AUTOSAR XML (schema 4-3-0)
package /Impl_SWC_INP_ARPkg
  swc implementation Impl_SWC_INP_type: programming-language=C, sw-version=1.0.0, vendor-id=0, behavior=SWC_INP_type_IB
    code-descriptors:
      code SRC: artifact-descriptors=autosar-engineering-object={short-label=EngObject, category=SWSRC}
    resource consumption ResourceConsumption
      memory section Mem_SWC_INP_CAL: size=0, sw-addrmethod=CAL, symbol=CAL
      memory section Mem_SWC_INP_CODE: size=0, sw-addrmethod=CODE, symbol=CODE
package /Impl_Type_INP_ARPkg
  16 x impl type:
    BINP_CAN1_outputs: category=STRUCTURE
      63 x element, all with category=TYPE_REFERENCE:
        VINP_CANMsgValidACBTMSC10000_flg: implementation-data-type=boolean
        VINP_CANMsgValidACBTMSC10001_flg: implementation-data-type=boolean
        VINP_CANMsgValidACBTMSC10004_flg: implementation-data-type=boolean
        VINP_CANMsgValidACBTMSC50000_flg: implementation-data-type=boolean
        VINP_CANMsgValidASC1A_flg: implementation-data-type=boolean
        VINP_CANMsgValidEBC1_flg: implementation-data-type=boolean
        VINP_CANMsgValidEBC2_flg: implementation-data-type=boolean
        VINP_CANMsgValidEBC5_flg: implementation-data-type=boolean
        VINP_CANMsgValidECASDM1_flg: implementation-data-type=boolean
        VINP_CANMsgValidEMC1EM1_flg: implementation-data-type=boolean
        VINP_CANMsgValidHRW_flg: implementation-data-type=boolean
        VINP_CANMsgValidTC1_flg: implementation-data-type=boolean
        VINP_ACAmbTemp_C: implementation-data-type=float32
        VINP_ACFanSpdSta_enum: implementation-data-type=uint8
        VINP_TM2BFaultCode_enum: implementation-data-type=uint8
        VINP_ACTempSetSta_C: implementation-data-type=float32
        VINP_ASC1KneelingInfo_enum: implementation-data-type=uint8
        VINP_ABSFullyOper_enum: implementation-data-type=uint8
        VINP_ABSOffroadSw_enum: implementation-data-type=uint8
        VINP_ASRBrakeCtrlAtc_enum: implementation-data-type=uint8
        VINP_ASREngCtrlAtc_enum: implementation-data-type=uint8
        VINP_ASRHillHolderSw_enum: implementation-data-type=uint8
        VINP_ASROffroadSw_enum: implementation-data-type=uint8
        VINP_ATCASRInfoSig_enum: implementation-data-type=uint8
        VINP_AcltrInterlockSw_enum: implementation-data-type=uint8
        VINP_AntiLBrakABSAct_enum: implementation-data-type=uint8
        VINP_BrakePedalPos_pct: implementation-data-type=float32
        VINP_EBSAmWarnLampSta_enum: implementation-data-type=uint8
        VINP_EBSBrakeSw_enum: implementation-data-type=uint8
        VINP_EBSRedWarnLampSta_enum: implementation-data-type=uint8
        VINP_EngAuxShutdownSw_enum: implementation-data-type=uint8
        VINP_EngDerateSw_enum: implementation-data-type=uint8
        VINP_EngRetSel_pct: implementation-data-type=float32
        VINP_HaltBrakeSw_enum: implementation-data-type=uint8
        VINP_RmAccelEnSw_enum: implementation-data-type=uint8
        VINP_SACtrlBrakeCtrl_SA: implementation-data-type=float32
        VINP_TractCtrlOvrSw_enum: implementation-data-type=uint8
        VINP_TrailerABSSta_enum: implementation-data-type=uint8
        VINP_TrailerABSWarnSig_enum: implementation-data-type=uint8
        VINP_FASpeed_kph: implementation-data-type=float32
        VINP_RelaSpdFALWheel_kph: implementation-data-type=float32
        VINP_RelaSpdFARWheel_kph: implementation-data-type=float32
        VINP_BrkTempeWarn_enum: implementation-data-type=uint8
        VINP_FndBrkUse_enum: implementation-data-type=uint8
        VINP_HaltBrkMode_enum: implementation-data-type=uint8
        VINP_HillHolderMode_enum: implementation-data-type=uint8
        VINP_ParkBrkActuFAct_enum: implementation-data-type=uint8
        VINP_XBRAcltnLimit_mps2: implementation-data-type=float32
        VINP_XBRActtrlMode_enum: implementation-data-type=uint8
        VINP_XBRSysSta_enum: implementation-data-type=uint8
        VINP_ECASAWarmLampSta_enum: implementation-data-type=uint8
        VINP_EM1CS_enum: implementation-data-type=uint8
        VINP_EM1Cnt_enum: implementation-data-type=uint8
        VINP_EM1OvrCtrlMBrk_enum: implementation-data-type=uint8
        VINP_EM1OvrCtrlMDriv_enum: implementation-data-type=uint8
        VINP_EM1OvrCtrlMPriBrk_enum: implementation-data-type=uint8
        VINP_EM1ReqTorqHRlsBrk_pct: implementation-data-type=float32
        VINP_EM1ReqTorqHRlsDri_pct: implementation-data-type=float32
        VINP_EM1ReqTorqLimBrk_pct: implementation-data-type=float32
        VINP_EM1ReqTorqLimDriv_pct: implementation-data-type=float32
        VINP_WhlSpeedFL_kph: implementation-data-type=float32
        VINP_DrivDirF_enum: implementation-data-type=uint8
        VINP_TransReqGear_enum: implementation-data-type=uint8
    BINP_CAN2_outputs: category=STRUCTURE
      element VINP_CANMsgValidIVIC1000_flg: implementation-data-type=boolean
      element VINP_IVIACFanSpdReqCmd_enum: implementation-data-type=uint8
    BINP_CAN3_outputs: category=STRUCTURE
      49 x element, all with category=TYPE_REFERENCE:
        VINP_CANMsgValidB2TMInfo_flg: implementation-data-type=boolean
        VINP_CANMsgValidB2VBattInfo1_flg: implementation-data-type=boolean
        VINP_CANMsgValidB2VCurrentLimit_flg: implementation-data-type=boolean
        VINP_CANMsgValidB2VFult132960_flg: implementation-data-type=boolean
        VINP_CANMsgValidB2VST1_flg: implementation-data-type=boolean
        VINP_CANMsgValidB2VST2_flg: implementation-data-type=boolean
        VINP_CANMsgValidB2VST4_flg: implementation-data-type=boolean
        VINP_CANMsgValidB2VST5_flg: implementation-data-type=boolean
        VINP_CANMsgValidEWP1_flg: implementation-data-type=boolean
        VINP_CANMsgValidTMMCUSta{1..3}_flg: implementation-data-type=boolean
        VINP_B2THVRlySta_enum: implementation-data-type=uint8
        VINP_B2VBI1BattType_enum: implementation-data-type=uint8
        VINP_B2VAPlsDischgCurr_A: implementation-data-type=float32
        VINP_B2VAvaPlsChgCurr_A: implementation-data-type=float32
        VINP_B2VHVILFault_flg: implementation-data-type=boolean
        VINP_B2VACChgConnSta_flg: implementation-data-type=boolean
        VINP_B2VACChgNegRlySta_enum: implementation-data-type=uint8
        VINP_B2VACChgPosRlySta_enum: implementation-data-type=uint8
        VINP_B2VBMUHVSta_enum: implementation-data-type=uint8
        VINP_B2VChgMode_enum: implementation-data-type=uint8
        VINP_B2VChgSta_enum: implementation-data-type=uint8
        VINP_B2VDCChgConnSta_enum: implementation-data-type=uint8
        VINP_B2VDCChgN1RlySta_enum: implementation-data-type=uint8
        VINP_B2VDCChgP1RlySta_enum: implementation-data-type=uint8
        VINP_B2VMainNegRlySta_enum: implementation-data-type=uint8
        VINP_B2VFaultCode_enum: implementation-data-type=uint8
        VINP_B2VFaultLv_enum: implementation-data-type=uint8
        VINP_B2VPackCurr_A: implementation-data-type=float32
        VINP_B2VPackInsideVol_V: implementation-data-type=float32
        VINP_B2VRqHVPwrOff_enum: implementation-data-type=uint8
        VINP_B2VSOC_pct: implementation-data-type=float32
        VINP_B2VMinTempPos_enum: implementation-data-type=uint8
        VINP_B2VCellMinVol_V: implementation-data-type=float32
        VINP_EWPPEFault_enum: implementation-data-type=uint8
        VINP_AtvDisChgEnFbk_flg: implementation-data-type=boolean
        VINP_MCUCtrlMdSta_enum: implementation-data-type=uint8
        VINP_MCUIGBTEnFbk_flg: implementation-data-type=boolean
        VINP_MotorSpd_rpm: implementation-data-type=float32
        VINP_MotorTrq_Nm: implementation-data-type=float32
        VINP_MCUFailGrade_enum: implementation-data-type=uint8
        VINP_MCUTemp_C: implementation-data-type=float32
        VINP_MCUTrqLimHi_Nm: implementation-data-type=float32
        VINP_MCUTrqLimLo_Nm: implementation-data-type=float32
        VINP_MotorTemp_C: implementation-data-type=float32
        VINP_MCUDCCur_A: implementation-data-type=float32
        VINP_MCUDCVol_V: implementation-data-type=float32
        VINP_MCUFailCode_enum: implementation-data-type=uint8
    BINP_CAN4_outputs: category=STRUCTURE
      51 x element, all with category=TYPE_REFERENCE:
        VINP_CANMsgValidZFRC1000_flg: implementation-data-type=boolean
        VINP_CANMsgValidZFRCE1000_flg: implementation-data-type=boolean
        VINP_CANMsgValidZRRCE1000_flg: implementation-data-type=boolean
        VINP_CANMsgValidZRRCE1001_flg: implementation-data-type=boolean
        VINP_CANMsgValidzGWCANRr1C500_flg: implementation-data-type=boolean
        VINP_ParkBrakeSW_enum: implementation-data-type=uint8
        VINP_AirPressureFC2_kPa: implementation-data-type=float32
        VINP_ZFRBCMAutoLightSWSta_flg: implementation-data-type=boolean
        VINP_ZFRBCMBrakeSta_flg: implementation-data-type=boolean
        VINP_ZFRBCMHBeamSWSta_flg: implementation-data-type=boolean
        VINP_ZFRBCMHeadLpSWSta_flg: implementation-data-type=boolean
        VINP_ZFRBCMLFTurnLpCSta_A: implementation-data-type=float32
        VINP_ZFRBCMLightSensorVSta_V: implementation-data-type=float32
        VINP_ZFRBCMPLampSta_flg: implementation-data-type=boolean
        VINP_ZFRBCMRFTurnLpCSta_A: implementation-data-type=float32
        VINP_ZFRBCMRFogLpSWSta_flg: implementation-data-type=boolean
        VINP_ZFRBCMSeatbeltSta_flg: implementation-data-type=boolean
        VINP_ZFRBCMWasherSWSta_flg: implementation-data-type=boolean
        VINP_ZFRBCMWiperASSta_flg: implementation-data-type=boolean
        VINP_ZFRBCMWiperHSWSta_flg: implementation-data-type=boolean
        VINP_ZFRBCMWiperLSWSta_flg: implementation-data-type=boolean
        VINP_ZRRBCMAllDoorSta_enum: implementation-data-type=uint8
        VINP_AirPressurePC3_kPa: implementation-data-type=float32
        VINP_AirPressureRC1_kPa: implementation-data-type=float32
        VINP_FDCCHASSISVCUEACPressSta_flg: implementation-data-type=boolean
        VINP_ZRRBCMCallingSWSta_flg: implementation-data-type=boolean
        VINP_ZRRBCMLRTurnLpCSta_A: implementation-data-type=float32
        VINP_ZRRBCMPLampSta_flg: implementation-data-type=boolean
        VINP_ZRRBCMRRTurnLpCSta_A: implementation-data-type=float32
        VINP_ZRRBCMSTOPSW2Sta_flg: implementation-data-type=boolean
        VINP_ZRRBCMSTOPSWSta_flg: implementation-data-type=boolean
        VINP_DCDCEnSta_enum: implementation-data-type=uint8
        VINP_DCDCErrLvSta_enum: implementation-data-type=uint8
        VINP_DCDCOutVolSta_V: implementation-data-type=float32
        VINP_DCDCTempSta_C: implementation-data-type=float32
        VINP_EACEnSta_enum: implementation-data-type=uint8
        VINP_EACErrLvSta_enum: implementation-data-type=uint8
        VINP_EACInvTempSta_C: implementation-data-type=float32
        VINP_EHPSEnSta_enum: implementation-data-type=uint8
        VINP_EHPSErrLvSta_enum: implementation-data-type=uint8
        VINP_EHPSInvTempSta_C: implementation-data-type=float32
        VINP_EHPSMotorSpdSta_rpm: implementation-data-type=float32
        VINP_PDUACRlySta_enum: implementation-data-type=uint8
        VINP_PDUDCDCEACEHPSHVLoopSta_enum: implementation-data-type=uint8
        VINP_PDUDCDCEACEHPSPreRlySta_enum: implementation-data-type=uint8
        VINP_PDUDCDCEACEHPSRlySta_enum: implementation-data-type=uint8
        VINP_PDUHVILSta_enum: implementation-data-type=uint8
        VINP_PDUMCUHVLoopSta_enum: implementation-data-type=uint8
        VINP_PDUMCUPosRlySta_enum: implementation-data-type=uint8
        VINP_PDUMCUPreRlySta_enum: implementation-data-type=uint8
        VINP_PDUSelfChkSta_enum: implementation-data-type=uint8
    BINP_APM_outputs: category=STRUCTURE
      58 x element, all with category=TYPE_REFERENCE:
        VINP_PASDRMR_cm: implementation-data-type=uint8
        VINP_PASDRML_cm: implementation-data-type=uint8
        VINP_PASDRCR_cm: implementation-data-type=uint8
        VINP_PASDRCL_cm: implementation-data-type=uint8
        VINP_PASDFMR_cm: implementation-data-type=uint8
        VINP_PASDFML_cm: implementation-data-type=uint8
        VINP_PASDFCR_cm: implementation-data-type=uint8
        VINP_PASDFCL_cm: implementation-data-type=uint8
        VINP_APSDRLR_cm: implementation-data-type=uint16
        VINP_APSDRLL_cm: implementation-data-type=uint16
        VINP_APSDFLR_cm: implementation-data-type=uint16
        VINP_APSDFLL_cm: implementation-data-type=uint16
        VINP_PASAFCL_enum: implementation-data-type=uint8
        VINP_PASARMR_enum: implementation-data-type=uint8
        VINP_PASARML_enum: implementation-data-type=uint8
        VINP_PASARCR_enum: implementation-data-type=uint8
        VINP_PASARCL_enum: implementation-data-type=uint8
        VINP_PASAFMR_enum: implementation-data-type=uint8
        VINP_PASAFML_enum: implementation-data-type=uint8
        VINP_PASAFCR_enum: implementation-data-type=uint8
        VINP_USSStaRMR_flg: implementation-data-type=boolean
        VINP_USSStaRML_flg: implementation-data-type=boolean
        VINP_USSStaRLR_flg: implementation-data-type=boolean
        VINP_USSStaRLL_flg: implementation-data-type=boolean
        VINP_USSStaRCR_flg: implementation-data-type=boolean
        VINP_USSStaRCL_flg: implementation-data-type=boolean
        VINP_USSStaFMR_flg: implementation-data-type=boolean
        VINP_USSStaFML_flg: implementation-data-type=boolean
        VINP_USSStaFLR_flg: implementation-data-type=boolean
        VINP_USSStaFLL_flg: implementation-data-type=boolean
        VINP_USSStaFCR_flg: implementation-data-type=boolean
        VINP_USSStaFCL_flg: implementation-data-type=boolean
        VINP_Chime_enum: implementation-data-type=uint8
        VINP_SNSRLayout_enum: implementation-data-type=uint8
        VINP_StaFSya_flg: implementation-data-type=boolean
        VINP_ModOperation_enum: implementation-data-type=uint8
        VINP_APSProgressPCT_pct: implementation-data-type=float32
        VINP_APSRQDisplay_enum: implementation-data-type=uint8
        VINP_APSSWVer_enum: implementation-data-type=uint8
        VINP_APSHWVer_enum: implementation-data-type=uint8
        VINP_APSExitCondition_enum: implementation-data-type=uint8
        VINP_APSAngleTarget_Deg: implementation-data-type=float32
        VINP_APSStaSystem_enum: implementation-data-type=uint8
        VINP_APSVRqEPASCtrl_flg: implementation-data-type=boolean
        VINP_APSRqEPASCtrl_flg: implementation-data-type=boolean
        VINP_APSReq_enum: implementation-data-type=uint8
        VINP_APSDecReq_mps2: implementation-data-type=float32
        VINP_APSDecReqA_flg: implementation-data-type=boolean
        VINP_APSShiftPosnReq_enum: implementation-data-type=uint8
        VINP_APSSpeedCMD_kph: implementation-data-type=float32
        VINP_APSVMCReqA_flg: implementation-data-type=boolean
        VINP_CAASSta_enum: implementation-data-type=uint8
        VINP_CAASVMCReqA_flg: implementation-data-type=boolean
        VINP_APSPwrReq_enum: implementation-data-type=uint8
        VINP_RAPSBCMLockReq_flg: implementation-data-type=boolean
        VINP_RAPSBCMLamp_enum: implementation-data-type=uint8
        VINP_RAPSErrWarnSta_enum: implementation-data-type=uint8
        VINP_RAPSErrLv1_flg: implementation-data-type=boolean
    BINP_DDM_outputs: category=STRUCTURE
      element VINP_ClearDTCcmd_flg: implementation-data-type=boolean
    BINP_DKC_outputs: category=STRUCTURE
      21 x element, all with category=TYPE_REFERENCE:
        VINP_DKCDecReVehData_enum: implementation-data-type=uint8
        VINP_DKCDecRemotePW_enum: implementation-data-type=uint8
        VINP_DKCDecPCommandToBCM_enum: implementation-data-type=uint8
        VINP_DKCDecPCommandToPTG_enum: implementation-data-type=uint8
        VINP_DKCDecPDKeyAreaLockUnlock_enum: implementation-data-type=uint8
        VINP_DKCDecPDKeyAreaPS_enum: implementation-data-type=uint8
        VINP_DKCDecPDKeyAreaPTG_enum: implementation-data-type=uint8
        VINP_DKCDecPDKeyWelcome_enum: implementation-data-type=uint8
        VINP_DKCDecPDkeyShowIVI_enum: implementation-data-type=uint8
        VINP_DKCDecPKeyMiss_flg: implementation-data-type=boolean
        VINP_DKCDecPKeyMode_enum: implementation-data-type=uint8
        VINP_DKCDecPUIDLowPower_flg: implementation-data-type=boolean
        VINP_TimeSNDKCFbk_cnt: implementation-data-type=uint32
        VINP_DKCDecryptionFail_flg: implementation-data-type=boolean
        VINP_NFCDoorSta_flg: implementation-data-type=boolean
        VINP_NFCLidASta_flg: implementation-data-type=boolean
        VINP_KeyFobAreaU16_enum: implementation-data-type=uint16
        VINP_UIDButtonCmd_enum: implementation-data-type=uint8
        VINP_BTConnectSta_enum: implementation-data-type=uint8
        VINP_UIDBatVoltx1000_V: implementation-data-type=uint16
        VINP_DKCBTRSSI_dB: implementation-data-type=sint8
    BINP_GPIO_outputs: category=STRUCTURE
      29 x element, all with category=TYPE_REFERENCE:
        VINP_AccelPedal1VolShortHigh_enum: implementation-data-type=uint8
        VINP_AccelPedal1VolShortLow_enum: implementation-data-type=uint8
        VINP_AccelPedal1Vol_V: implementation-data-type=float32
        VINP_AccelPedal1VolValid_flg: implementation-data-type=boolean
        VINP_AccelPedal2VolShortHigh_enum: implementation-data-type=uint8
        VINP_AccelPedal2VolShortLow_enum: implementation-data-type=uint8
        VINP_AccelPedal2Vol_V: implementation-data-type=float32
        VINP_AccelPedal2VolValid_flg: implementation-data-type=boolean
        VINP_BrakeSWGPIO_flg: implementation-data-type=boolean
        VINP_EmergencyExitSW_flg: implementation-data-type=boolean
        VINP_TailgateSW_flg: implementation-data-type=boolean
        VINP_LeftTurnSW_flg: implementation-data-type=boolean
        VINP_RightTurnSW_flg: implementation-data-type=boolean
        VINP_FrontDoorSW_flg: implementation-data-type=boolean
        VINP_MidDoorSW_flg: implementation-data-type=boolean
        VINP_OSDoorSwOpen_flg: implementation-data-type=boolean
        VINP_OSDoorSwClose_flg: implementation-data-type=boolean
        VINP_HazardSW_flg: implementation-data-type=boolean
        VINP_BrakeLampSW_flg: implementation-data-type=boolean
        VINP_TrunkHanSW_flg: implementation-data-type=boolean
        VINP_SeatSW_flg: implementation-data-type=boolean
        VINP_CrashSignalGPIO_flg: implementation-data-type=boolean
        VINP_HWID{1..4}_enum: implementation-data-type=uint8
        VINP_PushButton_flg: implementation-data-type=boolean
        VINP_AlcoholPass_flg: implementation-data-type=boolean
        VINP_BmsAplus_flg: implementation-data-type=boolean
    BINP_IMU_outputs: category=STRUCTURE
      12 x element, all with category=TYPE_REFERENCE, implementation-data-type=sint16:
        VINP_MemOffsetGyroX_raw16
        VINP_MemOffsetGyroY_raw16
        VINP_MemOffsetGyroZ_raw16
        VINP_MemOffsetAccX_raw16
        VINP_MemOffsetAccY_raw16
        VINP_MemOffsetAccZ_raw16
        VINP_SensingGyroX_raw16
        VINP_SensingGyroY_raw16
        VINP_SensingGyroZ_raw16
        VINP_SensingAccX_raw16
        VINP_SensingAccY_raw16
        VINP_SensingAccZ_raw16
    BINP_SYS_outputs: category=STRUCTURE
      308 x element, all with category=TYPE_REFERENCE:
        VINP_CarModel{1..3}_cnt: implementation-data-type=uint8
        VINP_ECU1_cnt: implementation-data-type=uint8
        VINP_ECU2_cnt: implementation-data-type=uint8
        VINP_Major1_cnt: implementation-data-type=uint8
        VINP_Major2_cnt: implementation-data-type=uint8
        VINP_Minor1_cnt: implementation-data-type=uint8
        VINP_Minor2_cnt: implementation-data-type=uint8
        VINP_Patch1_cnt: implementation-data-type=uint8
        VINP_Patch2_cnt: implementation-data-type=uint8
        VINP_Country1_cnt: implementation-data-type=uint8
        VINP_Country2_cnt: implementation-data-type=uint8
        VINP_Variation_cnt: implementation-data-type=uint8
        VINP_Dash1_cnt: implementation-data-type=uint8
        VINP_Change1_cnt: implementation-data-type=uint8
        VINP_Change2_cnt: implementation-data-type=uint8
        VINP_Dash2_cnt: implementation-data-type=uint8
        VINP_SHA{1..8}_cnt: implementation-data-type=uint8
        VINP_AcoreReadyToSlp_flg: implementation-data-type=boolean
        VINP_PwrReq_OTA_enum: implementation-data-type=uint8
        VINP_AllowMovThd_OTA_enum: implementation-data-type=uint8
        VINP_EvccAplusPwrUpReq_flg: implementation-data-type=boolean
        VINP_DrivetrainSelect_enum: implementation-data-type=uint8
        VINP_ReadFlashCorrect_flg: implementation-data-type=boolean
        VINP_FlashAntitheft_enum: implementation-data-type=uint8
        VINP_RandomnumberY_raw{1..8}: implementation-data-type=uint8
        VINP_FlashACModeMem_enum: implementation-data-type=uint8
        VINP_FlashFace_enum: implementation-data-type=uint8
        VINP_FlashFoot_enum: implementation-data-type=uint8
        VINP_FlashFrost_enum: implementation-data-type=uint8
        VINP_FlashFaceM_enum: implementation-data-type=uint8
        VINP_FlashFootM_enum: implementation-data-type=uint8
        VINP_FlashCCUSyncSts_enum: implementation-data-type=uint8
        VINP_FlashACForceOFF_flg: implementation-data-type=boolean
        VINP_FlashsigRecircSt_enum: implementation-data-type=uint8
        VINP_FlashRecAutoFlg_enum: implementation-data-type=uint8
        VINP_FlashAirIntenZone1M_enum: implementation-data-type=uint8
        VINP_Flashfdefog_enum: implementation-data-type=uint8
        VINP_FlashsigSetTempZon1St_C: implementation-data-type=uint8
        VINP_FlashsigSetTempZon2StM_C: implementation-data-type=uint8
        VINP_FlashCountAlarm_enum: implementation-data-type=uint8
        VINP_FlashMFSWTri_flg: implementation-data-type=boolean
        VINP_FlashMirrorFlodPos_flg: implementation-data-type=boolean
        VINP_FlashFuelDoorPos_flg: implementation-data-type=boolean
        VINP_FlashLockSetting_enum: implementation-data-type=uint8
        VINP_FlashMFRDNBrightReq_pct: implementation-data-type=uint8
        VINP_FlashRoomLampMode_enum: implementation-data-type=uint8
        VINP_FlashWiperFixMode_flg: implementation-data-type=boolean
        VINP_FlashIVIPTGUSStaSW_enum: implementation-data-type=uint8
        VINP_AnyNMID_flg: implementation-data-type=boolean
        VINP_CurrentNmState_enum: implementation-data-type=uint8
        VINP_NvmProtectSta_flg: implementation-data-type=boolean
        VINP_AuxBattVolmV_mV: implementation-data-type=uint16
        VINP_Pedal1Ref5V_V: implementation-data-type=float32
        VINP_Pedal2Ref5V_V: implementation-data-type=float32
        VINP_EAPS1MINMem_pct: implementation-data-type=float32
        VINP_EAPS2MINMem_pct: implementation-data-type=float32
        VINP_FlashHoodSW_flg: implementation-data-type=boolean
        VINP_FlashTailgateSW_flg: implementation-data-type=boolean
        VINP_FlashCTDLockSW_flg: implementation-data-type=boolean
        VINP_FlashTailgateHDSW_flg: implementation-data-type=boolean
        VINP_NetworkReqCalled_flg: implementation-data-type=boolean
        VINP_PmicBootReason_enum: implementation-data-type=uint8
        VINP_WisrBootReason_raw32: implementation-data-type=uint32
        VINP_FlashAPMDoorControlSta_flg: implementation-data-type=boolean
        VINP_AcoreRebootCmd_flg: implementation-data-type=boolean
        VINP_DIDGetDynoMode_flg: implementation-data-type=boolean
        VINP_CAN{1..6}BusOff_flg: implementation-data-type=boolean
        VINP_funAuto_flg: implementation-data-type=boolean
        VINP_DiagDRLOFF_flg: implementation-data-type=boolean
        VINP_DiagFMHT_s: implementation-data-type=float32
        VINP_DiagFLTC_mA: implementation-data-type=float32
        VINP_DiagFRTC_mA: implementation-data-type=float32
        VINP_DiagRLTC_mA: implementation-data-type=float32
        VINP_DiagRRTC_mA: implementation-data-type=float32
        VINP_USSConfig_raw8: implementation-data-type=u8_Array16_type
        VINP_TireSize_raw8: implementation-data-type=u8_Array16_type
        VINP_APSFunConfig_raw8: implementation-data-type=u8_Array16_type
        VINP_FlashfUnlockSingle_flg: implementation-data-type=boolean
        VINP_FlashRegenMode_enum: implementation-data-type=uint8
        VINP_FlashAmbFunEN_enum: implementation-data-type=uint8
        VINP_FlashAmbWelEN_enum: implementation-data-type=uint8
        VINP_FlashAmbDimEN_enum: implementation-data-type=uint8
        VINP_FlashAmbLinkDriSta_enum: implementation-data-type=uint8
        VINP_FlashAmbPwrWarnEN_enum: implementation-data-type=uint8
        VINP_FlashAmbODAEN_enum: implementation-data-type=uint8
        VINP_FlashAmbColorSta{1..5}_enum: implementation-data-type=uint8
        VINP_FlashAmbColorSta7_enum: implementation-data-type=uint8
        VINP_FlashAmbBrightnessSta{1..5}_enum: implementation-data-type=uint8
        VINP_FlashAmbBrightnessSta7_enum: implementation-data-type=uint8
        VINP_FlashTurnSwTSet123_enum: implementation-data-type=uint8
        VINP_FlashTurnSwTSet457_enum: implementation-data-type=uint8
        VINP_FlashAirIntZ3Sta_enum: implementation-data-type=uint8
        VINP_FlashPsEVentModeSta_enum: implementation-data-type=uint8
        VINP_FlashDrEVentModeSta_enum: implementation-data-type=uint8
        VINP_FlashDrEVentZSta_enum: implementation-data-type=uint8
        VINP_FlashCLEVentZSta_enum: implementation-data-type=uint8
        VINP_FlashPsEVentZSta_enum: implementation-data-type=uint8
        VINP_FlashCREVentZSta_enum: implementation-data-type=uint8
        VINP_FlashDrVentEN_enum: implementation-data-type=uint8
        VINP_FlashDrEVentYSta_enum: implementation-data-type=uint8
        VINP_FlashCLVentEN_enum: implementation-data-type=uint8
        VINP_FlashCLEVentYSta_enum: implementation-data-type=uint8
        VINP_FlashPsVentEN_enum: implementation-data-type=uint8
        VINP_FlashPsEVentYSta_enum: implementation-data-type=uint8
        VINP_FlashCRVentEN_enum: implementation-data-type=uint8
        VINP_FlashCREVentYSta_enum: implementation-data-type=uint8
        VINP_FlashFGSAirIntSta_enum: implementation-data-type=uint8
        VINP_FlashFGSChSta_enum: implementation-data-type=uint8
        VINP_FlashFGSIONSWSta_enum: implementation-data-type=uint8
        VINP_FlashWalkOutLkEN_enum: implementation-data-type=uint8
        VINP_FlashWalkInUnLkEN_enum: implementation-data-type=uint8
        VINP_FlashFollowMeENFun_enum: implementation-data-type=uint8
        VINP_ResetPedalZeroPosReq_enum: implementation-data-type=uint8
        VINP_FlashPTGUserHeight{1..5}_cnt: implementation-data-type=uint16
        VINP_FlashPTGUserHeight7_cnt: implementation-data-type=uint16
        VINP_FlashPTGOpenHeight12_enum: implementation-data-type=uint8
        VINP_FlashPTGOpenHeight34_enum: implementation-data-type=uint8
        VINP_FlashPTGOpenHeight57_enum: implementation-data-type=uint8
        VINP_NewNMSpec_flg: implementation-data-type=boolean
        VINP_FlashACCLevelSta12_enum: implementation-data-type=uint8
        VINP_FlashACCLevelSta34_enum: implementation-data-type=uint8
        VINP_FlashACCLevelSta57_enum: implementation-data-type=uint8
        VINP_AutoWipHSpdEN_flg: implementation-data-type=boolean
        VINP_WipRLSCmdHoldEN_flg: implementation-data-type=boolean
        VINP_WipRLSCmdHoldTime_s: implementation-data-type=uint8
        VINP_WipRLSCmdCutEN_flg: implementation-data-type=boolean
        VINP_WipRLSCmdCutTime_s: implementation-data-type=uint8
        VINP_FlashAutoLock_enum: implementation-data-type=uint8
        VINP_FlashAutoUnlock_enum: implementation-data-type=uint8
        VINP_VehicleType_enum: implementation-data-type=uint8
        VINP_SWCType_enum: implementation-data-type=uint8
        VINP_ECUGen1_cnt: implementation-data-type=uint8
        VINP_ECUGen2_cnt: implementation-data-type=uint8
        VINP_FlashMILDIST_km: implementation-data-type=float32
        VINP_FlashWARMUPS_cnt: implementation-data-type=uint8
        VINP_FlashCLRDIST_km: implementation-data-type=float32
        VINP_FlashMILTIME_min: implementation-data-type=uint16
        VINP_FlashCLRTIME_min: implementation-data-type=uint16
        VINP_FlashNUMPSATRIPSFLTMEMCLR_cnt: implementation-data-type=uint16
        VINP_FlashODOMETER_km: implementation-data-type=float32
        VINP_FlashPSAR_sec: implementation-data-type=uint32
        VINP_FlashPSAL_sec: implementation-data-type=uint32
        VINP_FlashIPSAR_sec: implementation-data-type=uint32
        VINP_FlashIPSAL_sec: implementation-data-type=uint32
        VINP_FlashCPSAR_sec: implementation-data-type=uint32
        VINP_FlashCPSAL_sec: implementation-data-type=uint32
        VINP_FlashHVBNAH_Ahr: implementation-data-type=float32
        VINP_FlashHVBNE_kWh: implementation-data-type=float32
        VINP_FlashIGNCNTR_cnt: implementation-data-type=uint16
        VINP_FlashTNBCPSAR_Ahr: implementation-data-type=float32
        VINP_FlashTNBCPSAL_Ahr: implementation-data-type=float32
        VINP_FlashTNECPSAR_kWh: implementation-data-type=float32
        VINP_FlashTNECPSAL_kWh: implementation-data-type=float32
        VINP_FlashTEBPSAR_kWh: implementation-data-type=float32
        VINP_FlashTEBPSAL_kWh: implementation-data-type=float32
        VINP_FlashTGEOVCR_kWh: implementation-data-type=float32
        VINP_FlashTGEOVCL_kWh: implementation-data-type=float32
        VINP_FlashGECHGOVCDCR_kWh: implementation-data-type=float32
        VINP_FlashGECHGOVCDCL_kWh: implementation-data-type=float32
        VINP_FlashGECHGOVCACR_kWh: implementation-data-type=float32
        VINP_FlashGECHGOVCACL_kWh: implementation-data-type=float32
        VINP_FlashRESSV2XENNONPSAR_kWh: implementation-data-type=float32
        VINP_FlashRESSV2XENNONPSAL_kWh: implementation-data-type=float32
        VINP_FlashPKERNumerator_kphsqr: implementation-data-type=uint32
        VINP_FlashPKELNumerator_kphsqr: implementation-data-type=uint32
        VINP_FlashResetCDEODTR_km: implementation-data-type=float32
        VINP_FlashAvgBattTempPSAR_C: implementation-data-type=float32
        VINP_FlashAvgBattTempPSAL_C: implementation-data-type=float32
        VINP_FlashAvgBattTempOVCR_C: implementation-data-type=float32
        VINP_FlashAvgBattTempOVCL_C: implementation-data-type=float32
        VINP_FlashAvgBattTempOFFR_C: implementation-data-type=float32
        VINP_FlashAvgBattTempOFFL_C: implementation-data-type=float32
        VINP_FlashQTYPSATRIPSR_cnt: implementation-data-type=uint32
        VINP_FlashQTYPSATRIPSL_cnt: implementation-data-type=uint32
        VINP_FlashRESSCNTDODRNGR_cnt: implementation-data-type=u16_Array8_type
        VINP_FlashRESSCNTDODRNGL_cnt: implementation-data-type=u16_Array8_type
        VINP_FlashETMATOER_kWh: implementation-data-type=float32
        VINP_FlashETMATOEL_kWh: implementation-data-type=float32
        VINP_FlashETMBTOER_kWh: implementation-data-type=float32
        VINP_FlashETMBTOEL_kWh: implementation-data-type=float32
        VINP_FlashRESSTIMESOCPSARNGR_s: implementation-data-type=u32_Array8_type
        VINP_FlashRESSTIMESOCPSARNGL_s: implementation-data-type=u32_Array8_type
        VINP_FlashRESSTIMESOCCHGRNGR_s: implementation-data-type=u32_Array8_type
        VINP_FlashRESSTIMESOCCHGRNGL_s: implementation-data-type=u32_Array8_type
        VINP_FlashRESSTIMESOCOFFRNGR_s: implementation-data-type=u32_Array8_type
        VINP_FlashRESSTIMESOCOFFRNGL_s: implementation-data-type=u32_Array8_type
        VINP_FlashMAXBATTEMPL_C: implementation-data-type=float32
        VINP_FlashMINBATTEMPL_C: implementation-data-type=float32
        VINP_FlashAVGBATTEMPL_sec: implementation-data-type=uint32
        VINP_FlashAVGBATTEMPL_C: implementation-data-type=float32
        VINP_FlashBattTempPSAR_sec: implementation-data-type=uint32
        VINP_FlashBattTempPSAL_sec: implementation-data-type=uint32
        VINP_FlashOVCR_sec: implementation-data-type=uint32
        VINP_FlashOVCL_sec: implementation-data-type=uint32
        VINP_FlashOFFR_sec: implementation-data-type=uint32
        VINP_FlashOFFL_sec: implementation-data-type=uint32
        VINP_VinCode_cnt: implementation-data-type=u8_Array17_type
        VINP_FlashHMIKey{1..8}Func_enum: implementation-data-type=uint8
        VINP_FlashAutoWipHSpdEN_flg: implementation-data-type=boolean
        VINP_PmicBootPath_raw32: implementation-data-type=uint32
        VINP_FlashTPMModelVersion_raw: implementation-data-type=uint8
        VINP_FlashTPMModelVersionChkSum_raw: implementation-data-type=uint8
        VINP_FlashDIDModelVersion_raw: implementation-data-type=uint8
        VINP_FlashDIDModelVersionChkSum_raw: implementation-data-type=uint8
        VINP_SOCDisUsed_flg: implementation-data-type=boolean
        VINP_FlashAirIntenZone1MSet{2..5}_enum: implementation-data-type=uint8
        VINP_FlashAirIntenZone1MSet7_enum: implementation-data-type=uint8
        VINP_FlashAirIntenZone3MSet{2..5}_enum: implementation-data-type=uint8
        VINP_FlashAirIntenZone3MSet7_enum: implementation-data-type=uint8
        VINP_FlashFGSChStaSet457_enum: implementation-data-type=uint8
        VINP_FlashFGSAirIntStaSet457_enum: implementation-data-type=uint8
        VINP_FlashDrEVentModeStaSet457_enum: implementation-data-type=uint8
        VINP_FlashPsEVentModeStaSet457_enum: implementation-data-type=uint8
        VINP_FlashDrEVentZStaSet{2..5}_enum: implementation-data-type=uint8
        VINP_FlashDrEVentZStaSet7_enum: implementation-data-type=uint8
        VINP_FlashCLEVentZStaSet{2..5}_enum: implementation-data-type=uint8
        VINP_FlashCLEVentZStaSet7_enum: implementation-data-type=uint8
        VINP_FlashPsEVentZStaSet{2..5}_enum: implementation-data-type=uint8
        VINP_FlashPsEVentZStaSet7_enum: implementation-data-type=uint8
        VINP_FlashCREVentZStaSet{2..5}_enum: implementation-data-type=uint8
        VINP_FlashCREVentZStaSet7_enum: implementation-data-type=uint8
        VINP_FlashDrEVentYStaSet{2..5}_enum: implementation-data-type=uint8
        VINP_FlashDrEVentYStaSet7_enum: implementation-data-type=uint8
        VINP_FlashCLEVentYStaSet{2..5}_enum: implementation-data-type=uint8
        VINP_FlashCLEVentYStaSet7_enum: implementation-data-type=uint8
        VINP_FlashPsEVentYStaSet{2..5}_enum: implementation-data-type=uint8
        VINP_FlashPsEVentYStaSet7_enum: implementation-data-type=uint8
        VINP_FlashCREVentYStaSet{2..5}_enum: implementation-data-type=uint8
        VINP_FlashCREVentYStaSet7_enum: implementation-data-type=uint8
        VINP_FlashACModeSet457_enum: implementation-data-type=uint8
        VINP_FlashSettempZon1Set{2..5}_enum: implementation-data-type=uint8
        VINP_FlashSettempZon1Set7_enum: implementation-data-type=uint8
        VINP_FlashJugKeepUnLZone_flg: implementation-data-type=boolean
        VINP_DrivingMode_cnt: implementation-data-type=uint8
        VINP_ModelYear_cnt: implementation-data-type=uint8
    BINP_TPMS_outputs: category=STRUCTURE
      52 x element, all with category=TYPE_REFERENCE:
        VINP_TPMSDataIn_flg: implementation-data-type=boolean
        VINP_TPMSID_raw: implementation-data-type=uint32
        VINP_TPMSPressure_raw: implementation-data-type=uint8
        VINP_TPMSTemp_raw: implementation-data-type=uint8
        VINP_TPMSSta_enum: implementation-data-type=uint8
        VINP_TPMSPressureMi_raw: implementation-data-type=uint8
        VINP_TPMSCRC_crc: implementation-data-type=uint8
        VINP_TPMSCRCCalc_crc: implementation-data-type=uint8
        VINP_TPMSFAT_flg: implementation-data-type=boolean
        VINP_TPMSBattLow_flg: implementation-data-type=boolean
        VINP_TPMSStorge_flg: implementation-data-type=boolean
        VINP_LFID_raw: implementation-data-type=uint32
        VINP_RFID_raw: implementation-data-type=uint32
        VINP_LRID_raw: implementation-data-type=uint32
        VINP_RRID_raw: implementation-data-type=uint32
        VINP_ChkStorge_flg: implementation-data-type=boolean
        VINP_ChkLFID_raw: implementation-data-type=uint32
        VINP_ChkRFID_raw: implementation-data-type=uint32
        VINP_ChkLRID_raw: implementation-data-type=uint32
        VINP_ChkRRID_raw: implementation-data-type=uint32
        VINP_FlashLFSensorFail_flg: implementation-data-type=boolean
        VINP_FlashRFSensorFail_flg: implementation-data-type=boolean
        VINP_FlashLRSensorFail_flg: implementation-data-type=boolean
        VINP_FlashRRSensorFail_flg: implementation-data-type=boolean
        VINP_FlashLFWheelPSW_raw8: implementation-data-type=uint8
        VINP_FlashRFWheelPSW_raw8: implementation-data-type=uint8
        VINP_FlashLRWheelPSW_raw8: implementation-data-type=uint8
        VINP_FlashRRWheelPSW_raw8: implementation-data-type=uint8
        VINP_FlashLFPindi_enum: implementation-data-type=uint8
        VINP_FlashRFPindi_enum: implementation-data-type=uint8
        VINP_FlashLRPindi_enum: implementation-data-type=uint8
        VINP_FlashRRPindi_enum: implementation-data-type=uint8
        VINP_FlashLFP20_raw8: implementation-data-type=uint8
        VINP_FlashRFP20_raw8: implementation-data-type=uint8
        VINP_FlashLRP20_raw8: implementation-data-type=uint8
        VINP_FlashRRP20_raw8: implementation-data-type=uint8
        VINP_FlashLFWheelPress_raw8: implementation-data-type=uint8
        VINP_FlashRFWheelPress_raw8: implementation-data-type=uint8
        VINP_FlashLRWheelPress_raw8: implementation-data-type=uint8
        VINP_FlashRRWheelPress_raw8: implementation-data-type=uint8
        VINP_FlashLFWheelTemp_C: implementation-data-type=uint8
        VINP_FlashRFWheelTemp_C: implementation-data-type=uint8
        VINP_FlashLRWheelTemp_C: implementation-data-type=uint8
        VINP_FlashRRWheelTemp_C: implementation-data-type=uint8
        VINP_FlashunlearnSfali_flg: implementation-data-type=boolean
        VINP_S{1..4}ID_raw: implementation-data-type=uint32
        VINP_Prepresstemptrust_flg: implementation-data-type=boolean
        VINP_TPMSSensorIDRegSta_enum: implementation-data-type=uint8
        VINP_TPMSTrigger_flg: implementation-data-type=boolean
    u8_Array16_type: category=ARRAY
      element u8_Array16: category=VALUE, array-size=16, array-size-semantics=FIXED-SIZE, base-type=uint8
    u16_Array8_type: category=ARRAY
      element u16_Array8: category=VALUE, array-size=8, array-size-semantics=FIXED-SIZE, base-type=uint16
    u8_Array8_type: category=ARRAY
      element u8_Array8: category=VALUE, array-size=8, array-size-semantics=FIXED-SIZE, base-type=uint8
    u32_Array8_type: category=ARRAY
      element u32_Array8: category=VALUE, array-size=8, array-size-semantics=FIXED-SIZE, base-type=uint32
    u8_Array17_type: category=ARRAY
      element u8_Array17: category=VALUE, array-size=17, array-size-semantics=FIXED-SIZE, base-type=uint8
package /Interface_INP_ARPkg
  11 x sender receiver interface:
    IF_BINP_CAN1_outputs
      data BINP_CAN1_outputs: type=BINP_CAN1_outputs
    IF_BINP_CAN2_outputs
      data BINP_CAN2_outputs: type=BINP_CAN2_outputs
    IF_BINP_CAN3_outputs
      data BINP_CAN3_outputs: type=BINP_CAN3_outputs
    IF_BINP_CAN4_outputs
      data BINP_CAN4_outputs: type=BINP_CAN4_outputs
    IF_BINP_APM_outputs
      data BINP_APM_outputs: type=BINP_APM_outputs
    IF_BINP_DDM_outputs
      data BINP_DDM_outputs: type=BINP_DDM_outputs
    IF_BINP_DKC_outputs
      data BINP_DKC_outputs: type=BINP_DKC_outputs
    IF_BINP_GPIO_outputs
      data BINP_GPIO_outputs: type=BINP_GPIO_outputs
    IF_BINP_IMU_outputs
      data BINP_IMU_outputs: type=BINP_IMU_outputs
    IF_BINP_SYS_outputs
      data BINP_SYS_outputs: type=BINP_SYS_outputs
    IF_BINP_TPMS_outputs
      data BINP_TPMS_outputs: type=BINP_TPMS_outputs
package /SWC_INP_ARPkg
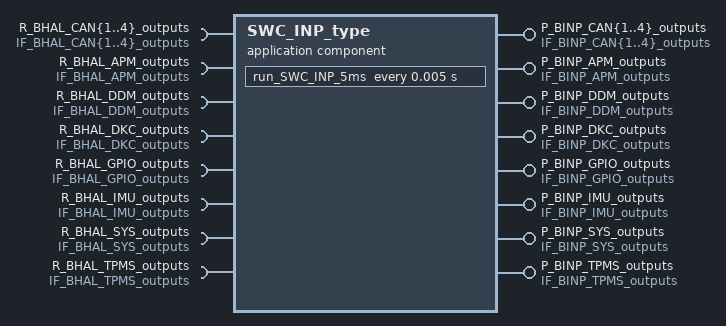
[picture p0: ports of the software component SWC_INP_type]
  application sw component type SWC_INP_type
    11 x provide port:
      P_BINP_CAN{1..4}_outputs: provided-interface=IF_BINP_CAN{1..4}_outputs
      P_BINP_APM_outputs: provided-interface=IF_BINP_APM_outputs
      P_BINP_DDM_outputs: provided-interface=IF_BINP_DDM_outputs
      P_BINP_DKC_outputs: provided-interface=IF_BINP_DKC_outputs
      P_BINP_GPIO_outputs: provided-interface=IF_BINP_GPIO_outputs
      P_BINP_IMU_outputs: provided-interface=IF_BINP_IMU_outputs
      P_BINP_SYS_outputs: provided-interface=IF_BINP_SYS_outputs
      P_BINP_TPMS_outputs: provided-interface=IF_BINP_TPMS_outputs
    11 x require port:
      R_BHAL_CAN{1..4}_outputs: required-interface=IF_BHAL_CAN{1..4}_outputs
      R_BHAL_APM_outputs: required-interface=IF_BHAL_APM_outputs
      R_BHAL_DDM_outputs: required-interface=IF_BHAL_DDM_outputs
      R_BHAL_DKC_outputs: required-interface=IF_BHAL_DKC_outputs
      R_BHAL_GPIO_outputs: required-interface=IF_BHAL_GPIO_outputs
      R_BHAL_IMU_outputs: required-interface=IF_BHAL_IMU_outputs
      R_BHAL_SYS_outputs: required-interface=IF_BHAL_SYS_outputs
      R_BHAL_TPMS_outputs: required-interface=IF_BHAL_TPMS_outputs
    behavior SWC_INP_type_IB: handle-termination-and-restart=NO-SUPPORT
      timing event TE_INP_5ms: start-on-event=run_SWC_INP_5ms, period=0.005
      runnable run_SWC_INP_5ms
        data-receive-point-by-arguments:
          11 x access:
            drparg_BHAL_CAN{1..4}_outputs: accessed-variable=R_BHAL_CAN{1..4}_outputs.BHAL_CAN{1..4}_outputs
            drparg_BHAL_APM_outputs: accessed-variable=R_BHAL_APM_outputs.BHAL_APM_outputs
            drparg_BHAL_DDM_outputs: accessed-variable=R_BHAL_DDM_outputs.BHAL_DDM_outputs
            drparg_BHAL_DKC_outputs: accessed-variable=R_BHAL_DKC_outputs.BHAL_DKC_outputs
            drparg_BHAL_GPIO_outputs: accessed-variable=R_BHAL_GPIO_outputs.BHAL_GPIO_outputs
            drparg_BHAL_IMU_outputs: accessed-variable=R_BHAL_IMU_outputs.BHAL_IMU_outputs
            drparg_BHAL_SYS_outputs: accessed-variable=R_BHAL_SYS_outputs.BHAL_SYS_outputs
            drparg_BHAL_TPMS_outputs: accessed-variable=R_BHAL_TPMS_outputs.BHAL_TPMS_outputs
        data-send-points:
          11 x access:
            dsp_BINP_CAN{1..4}_outputs: accessed-variable=P_BINP_CAN{1..4}_outputs.BINP_CAN{1..4}_outputs
            dsp_BINP_APM_outputs: accessed-variable=P_BINP_APM_outputs.BINP_APM_outputs
            dsp_BINP_DDM_outputs: accessed-variable=P_BINP_DDM_outputs.BINP_DDM_outputs
            dsp_BINP_DKC_outputs: accessed-variable=P_BINP_DKC_outputs.BINP_DKC_outputs
            dsp_BINP_GPIO_outputs: accessed-variable=P_BINP_GPIO_outputs.BINP_GPIO_outputs
            dsp_BINP_IMU_outputs: accessed-variable=P_BINP_IMU_outputs.BINP_IMU_outputs
            dsp_BINP_SYS_outputs: accessed-variable=P_BINP_SYS_outputs.BINP_SYS_outputs
            dsp_BINP_TPMS_outputs: accessed-variable=P_BINP_TPMS_outputs.BINP_TPMS_outputs
